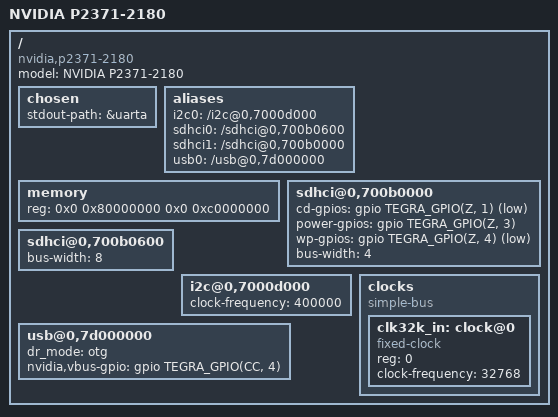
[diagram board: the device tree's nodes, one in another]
/dts-v1/;

#include "tegra210.dtsi"

/ {
	model = "NVIDIA P2371-2180";
	compatible = "nvidia,p2371-2180", "nvidia,tegra210";

	chosen {
		stdout-path = &uarta;
	};

	aliases {
		i2c0 = "/i2c@0,7000d000";
		sdhci0 = "/sdhci@0,700b0600";
		sdhci1 = "/sdhci@0,700b0000";
		usb0 = "/usb@0,7d000000";
	};

	memory {
		reg = <0x0 0x80000000 0x0 0xc0000000>;
	};

	sdhci@0,700b0000 {
		status = "okay";
		cd-gpios = <&gpio TEGRA_GPIO(Z, 1) GPIO_ACTIVE_LOW>;
		power-gpios = <&gpio TEGRA_GPIO(Z, 3) GPIO_ACTIVE_HIGH>;
		wp-gpios = <&gpio TEGRA_GPIO(Z, 4) GPIO_ACTIVE_LOW>;
		bus-width = <4>;
	};

	sdhci@0,700b0600 {
		status = "okay";
		bus-width = <8>;
	};

	i2c@0,7000d000 {
		status = "okay";
		clock-frequency = <400000>;
	};

	usb@0,7d000000 {
		status = "okay";
		dr_mode = "otg";
		nvidia,vbus-gpio = <&gpio TEGRA_GPIO(CC, 4) GPIO_ACTIVE_HIGH>;
	};

	clocks {
		compatible = "simple-bus";
		#address-cells = <1>;
		#size-cells = <0>;

		clk32k_in: clock@0 {
			compatible = "fixed-clock";
			reg = <0>;
			#clock-cells = <0>;
			clock-frequency = <32768>;
		};
	};
};
